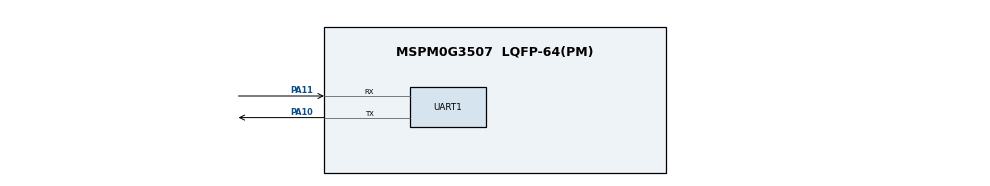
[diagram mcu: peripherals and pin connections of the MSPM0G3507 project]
/**
 * These arguments were used when this file was generated. They will be automatically applied on subsequent loads
 * via the GUI or CLI. Run CLI with '--help' for additional information on how to override these arguments.
 * @cliArgs --device "MSPM0G350X" --part "Default" --package "LQFP-64(PM)" --product "mspm0_sdk@2.10.00.04"
 * @v2CliArgs --device "MSPM0G3507" --package "LQFP-64(PM)" --product "mspm0_sdk@2.10.00.04"
 * @versions {"tool":"1.27.1+4634"}
 */

/**
 * Import the modules used in this configuration.
 */
const GPIO    = scripting.addModule("/ti/driverlib/GPIO", {}, false);
const GPIO1   = GPIO.addInstance();
const SYSCTL  = scripting.addModule("/ti/driverlib/SYSCTL");
const SYSTICK = scripting.addModule("/ti/driverlib/SYSTICK");
const UART    = scripting.addModule("/ti/driverlib/UART", {}, false);
const UART1   = UART.addInstance();

/**
 * Write custom configuration values to the imported modules.
 */
const gate7  = system.clockTree["MFCLKGATE"];
gate7.enable = true;

GPIO1.$name                          = "LCD";
GPIO1.port                           = "PORTA";
GPIO1.associatedPins.create(8);
GPIO1.associatedPins[0].$name        = "SCL";
GPIO1.associatedPins[0].initialValue = "SET";
GPIO1.associatedPins[0].assignedPin  = "7";
GPIO1.associatedPins[1].$name        = "SDA";
GPIO1.associatedPins[1].initialValue = "SET";
GPIO1.associatedPins[1].assignedPin  = "12";
GPIO1.associatedPins[2].$name        = "RES";
GPIO1.associatedPins[2].initialValue = "SET";
GPIO1.associatedPins[2].assignedPin  = "18";
GPIO1.associatedPins[3].$name        = "DC";
GPIO1.associatedPins[3].initialValue = "SET";
GPIO1.associatedPins[3].assignedPin  = "16";
GPIO1.associatedPins[4].$name        = "FSO";
GPIO1.associatedPins[4].direction    = "INPUT";
GPIO1.associatedPins[5].$name        = "CS1";
GPIO1.associatedPins[6].$name        = "CS2";
GPIO1.associatedPins[7].$name        = "BLK";

const Board = scripting.addModule("/ti/driverlib/Board", {}, false);

SYSCTL.forceDefaultClkConfig = true;
SYSCTL.clockTreeEn           = true;

SYSTICK.periodEnable      = true;
SYSTICK.systickEnable     = true;
SYSTICK.interruptPriority = "0";
SYSTICK.period            = 32;

UART1.$name                    = "UART_0";
UART1.uartClkSrc               = "MFCLK";
UART1.enabledInterrupts        = ["RX"];
UART1.peripheral.$assign       = "UART0";
UART1.peripheral.rxPin.$assign = "PA11";
UART1.peripheral.txPin.$assign = "PA10";
UART1.txPinConfig.$name        = "ti_driverlib_gpio_GPIOPinGeneric0";
UART1.rxPinConfig.$name        = "ti_driverlib_gpio_GPIOPinGeneric1";

/**
 * Pinmux solution for unlocked pins/peripherals. This ensures that minor changes to the automatic solver in a future
 * version of the tool will not impact the pinmux you originally saw.  These lines can be completely deleted in order to
 * re-solve from scratch.
 */
GPIO1.associatedPins[0].pin.$suggestSolution = "PA7";
GPIO1.associatedPins[1].pin.$suggestSolution = "PA12";
GPIO1.associatedPins[2].pin.$suggestSolution = "PA18";
GPIO1.associatedPins[3].pin.$suggestSolution = "PA16";
GPIO1.associatedPins[4].pin.$suggestSolution = "PA17";
GPIO1.associatedPins[5].pin.$suggestSolution = "PA15";
GPIO1.associatedPins[6].pin.$suggestSolution = "PA14";
GPIO1.associatedPins[7].pin.$suggestSolution = "PA13";
Board.peripheral.$suggestSolution            = "DEBUGSS";
Board.peripheral.swclkPin.$suggestSolution   = "PA20";
Board.peripheral.swdioPin.$suggestSolution   = "PA19";
